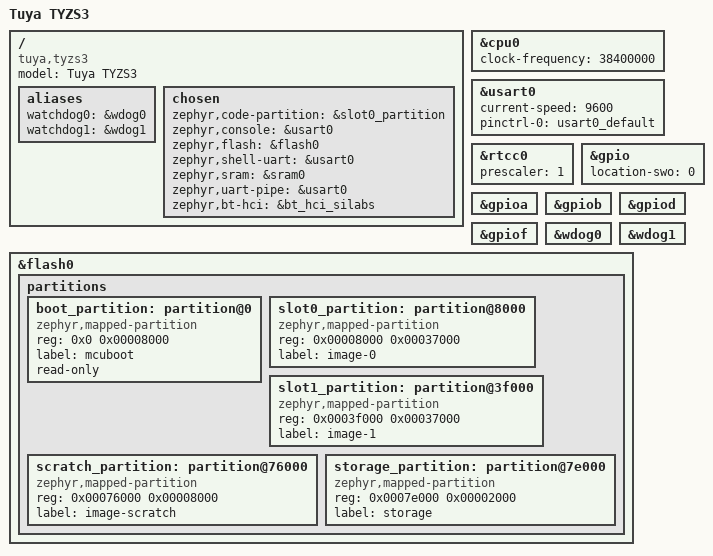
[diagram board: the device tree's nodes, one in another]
/*
 * Copyright (c) 2020 Piotr Mienkowski
 *
 * SPDX-License-Identifier: Apache-2.0
 */

/dts-v1/;
#include <silabs/xg13/efr32mg13p732f512gm48.dtsi>
#include "tyzs3-pinctrl.dtsi"

/ {
	model = "Tuya TYZS3";
	compatible = "tuya,tyzs3", "silabs,efr32mg13p";

	/* These aliases are provided for compatibility with samples */
	aliases {
		watchdog0 = &wdog0;
		watchdog1 = &wdog1;
	};

	chosen {
		zephyr,code-partition = &slot0_partition;
		zephyr,console = &usart0;
		zephyr,flash = &flash0;
		zephyr,shell-uart = &usart0;
		zephyr,sram = &sram0;
		zephyr,uart-pipe = &usart0;
		zephyr,bt-hci = &bt_hci_silabs;
	};
};

&cpu0 {
	clock-frequency = <38400000>;
};

&usart0 {
	current-speed = <9600>;
	pinctrl-0 = <&usart0_default>;
	pinctrl-names = "default";
	status = "okay";
};

&rtcc0 {
	prescaler = <1>;
	status = "okay";
};

&gpio {
	location-swo = <0>;
	status = "okay";
};

&gpioa {
	status = "okay";
};

&gpiob {
	status = "okay";
};

&gpiod {
	status = "okay";
};

&gpiof {
	status = "okay";
};

&wdog0 {
	status = "okay";
};

&wdog1 {
	status = "okay";
};

&flash0 {
	partitions {
		ranges;
		#address-cells = <1>;
		#size-cells = <1>;

		/* Reserve 32 kB for the bootloader */
		boot_partition: partition@0 {
			compatible = "zephyr,mapped-partition";
			reg = <0x0 0x00008000>;
			label = "mcuboot";
			read-only;
		};

		/* Reserve 220 kB for the application in slot 0 */
		slot0_partition: partition@8000 {
			compatible = "zephyr,mapped-partition";
			reg = <0x00008000 0x00037000>;
			label = "image-0";
		};

		/* Reserve 220 kB for the application in slot 1 */
		slot1_partition: partition@3f000 {
			compatible = "zephyr,mapped-partition";
			reg = <0x0003f000 0x00037000>;
			label = "image-1";
		};

		/* Reserve 32 kB for the scratch partition */
		scratch_partition: partition@76000 {
			compatible = "zephyr,mapped-partition";
			reg = <0x00076000 0x00008000>;
			label = "image-scratch";
		};

		/* Set 8Kb of storage at the end of the 512KB of flash */
		storage_partition: partition@7e000 {
			compatible = "zephyr,mapped-partition";
			reg = <0x0007e000 0x00002000>;
			label = "storage";
		};
	};
};
